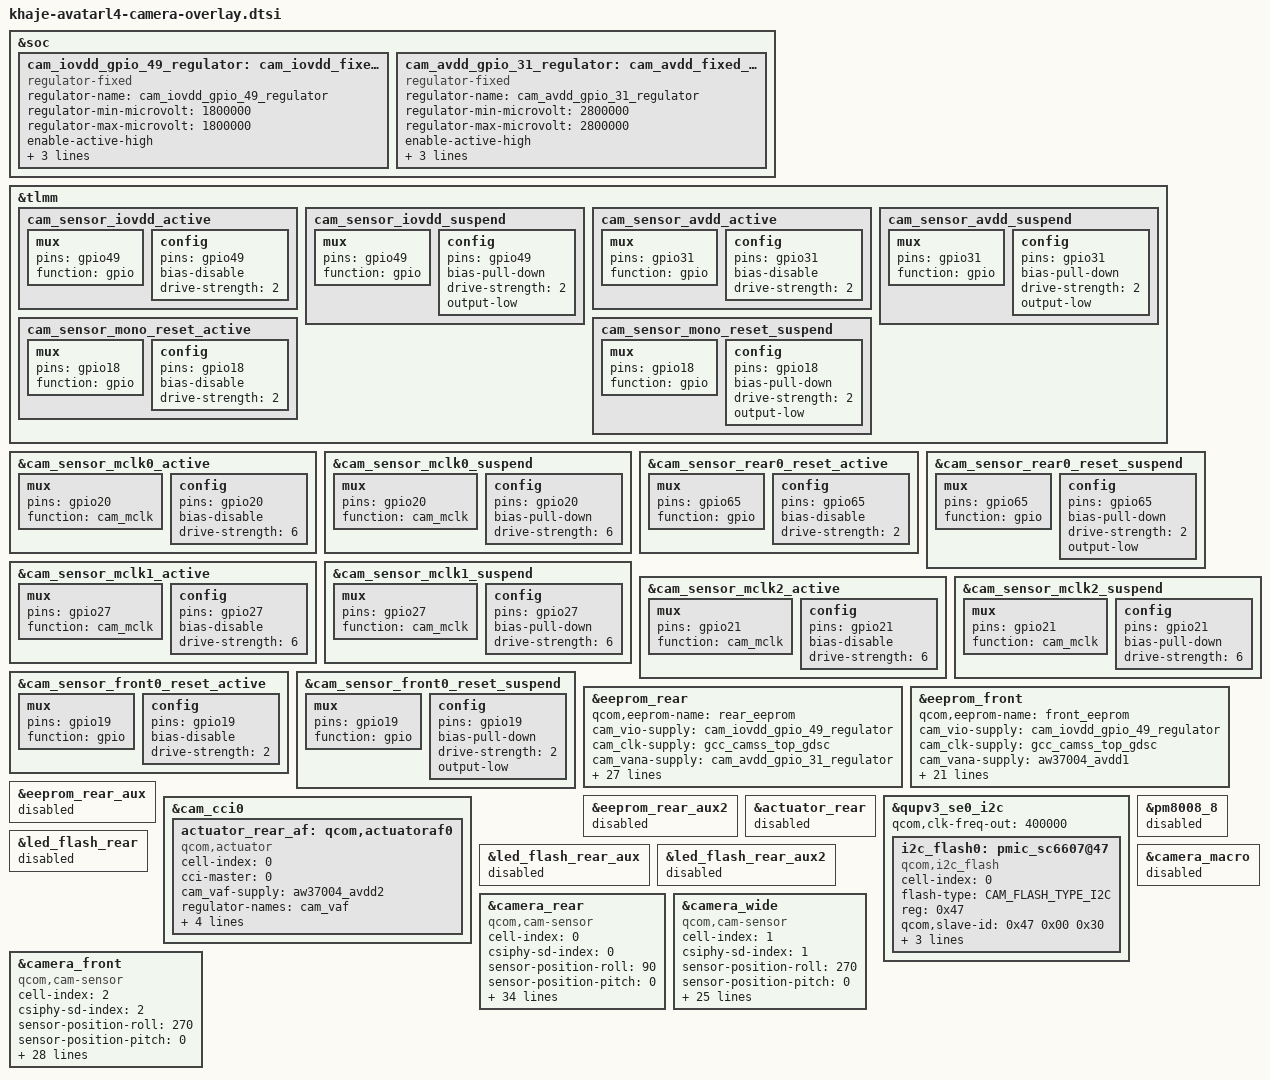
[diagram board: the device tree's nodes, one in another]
//khaje-camera-sensor-qrd.dtsi

&soc {
    cam_iovdd_gpio_49_regulator:cam_iovdd_fixed_regulator {
        compatible = "regulator-fixed";
        regulator-name = "cam_iovdd_gpio_49_regulator";
        regulator-min-microvolt = <1800000>;
        regulator-max-microvolt = <1800000>;
        enable-active-high;
        gpio = <&tlmm 49 0>;
        pinctrl-names = "cam_default","cam_suspend";
        pinctrl-0 = <&cam_sensor_iovdd_active>;
        pinctrl-1 = <&cam_sensor_iovdd_suspend>;
    };
    cam_avdd_gpio_31_regulator:cam_avdd_fixed_regulator {
        compatible = "regulator-fixed";
        regulator-name = "cam_avdd_gpio_31_regulator";
        regulator-min-microvolt = <2800000>;
        regulator-max-microvolt = <2800000>;
        enable-active-high;
        gpio = <&tlmm 31 0>;
        pinctrl-names = "cam_default","cam_suspend";
        pinctrl-0 = <&cam_sensor_avdd_active>;
        pinctrl-1 = <&cam_sensor_avdd_suspend>;
    };
};

&tlmm {

    cam_sensor_iovdd_active: cam_sensor_iovdd_active {
        mux {
            pins = "gpio49";
            function = "gpio";
        };
        config {
            pins = "gpio49";
            bias-disable; /* No PULL */
            drive-strength = <2>; /* 2 MA */
        };
    };
    cam_sensor_iovdd_suspend: cam_sensor_iovdd_suspend {
        mux {
            pins = "gpio49";
            function = "gpio";
        };
        config {
            pins = "gpio49";
            bias-pull-down; /* PULL DOWN */
            drive-strength = <2>; /* 2 MA */
            output-low;
        };
    };
    cam_sensor_avdd_active: cam_sensor_avdd_active {
        mux {
            pins = "gpio31";
            function = "gpio";
        };
        config {
            pins = "gpio31";
            bias-disable; /* No PULL */
            drive-strength = <2>; /* 2 MA */
        };
    };
    cam_sensor_avdd_suspend: cam_sensor_avdd_suspend {
        mux {
            pins = "gpio31";
            function = "gpio";
        };
        config {
            pins = "gpio31";
            bias-pull-down; /* PULL DOWN */
            drive-strength = <2>; /* 2 MA */
            output-low;
        };
    };

    cam_sensor_mono_reset_active: cam_sensor_mono_reset_active {
        mux {
            pins = "gpio18";
            function = "gpio";
        };
        config {
            pins = "gpio18";
            bias-disable; /* No PULL */
            drive-strength = <2>; /* 2 MA */
        };
    };
    cam_sensor_mono_reset_suspend: cam_sensor_mono_reset_suspend {
        mux {
            pins = "gpio18";
            function = "gpio";
        };
        config {
            pins = "gpio18";
            bias-pull-down; /* PULL DOWN */
            drive-strength = <2>; /* 2 MA */
            output-low;
        };
    };
};

&cam_sensor_mclk0_active {
    /* MCLK 0*/
    mux {
        pins = "gpio20";
        function = "cam_mclk";
    };

    config {
        pins = "gpio20";
        bias-disable; /* No PULL */
        drive-strength = <6>; /* 2 MA */
    };
};

&cam_sensor_mclk0_suspend {
    /* MCLK 0*/
    mux {
        pins = "gpio20";
        function = "cam_mclk";
    };

    config {
        pins = "gpio20";
        bias-pull-down; /* PULL DOWN */
        drive-strength = <6>; /* 2 MA */
    };
};

&cam_sensor_rear0_reset_active {
    mux {
        pins = "gpio65";
        function = "gpio";
    };
    config {
        pins = "gpio65";
        bias-disable; /* No PULL */
        drive-strength = <2>; /* 2 MA */
    };
};

&cam_sensor_rear0_reset_suspend {
    mux {
        pins = "gpio65";
        function = "gpio";
    };
    config {
        pins = "gpio65";
        bias-pull-down; /* PULL DOWN */
        drive-strength = <2>; /* 2 MA */
        output-low;
    };
};

&cam_sensor_mclk1_active {
    /* MCLK 1*/
    mux {
        pins = "gpio27";
        function = "cam_mclk";
    };

    config {
        pins = "gpio27";
        bias-disable; /* No PULL */
        drive-strength = <6>; /* 2 MA */
    };
};
&cam_sensor_mclk1_suspend {
    /* MCLK 1*/
    mux {
        pins = "gpio27";
        function = "cam_mclk";
    };

    config {
        pins = "gpio27";
        bias-pull-down; /* PULL DOWN */
        drive-strength = <6>; /* 2 MA */
    };
};

&cam_sensor_mclk2_active {
    /* MCLK 0*/
    mux {
        pins = "gpio21";
        function = "cam_mclk";
    };

    config {
        pins = "gpio21";
        bias-disable; /* No PULL */
        drive-strength = <6>; /* 2 MA */
    };
};

&cam_sensor_mclk2_suspend {
    /* MCLK 0*/
    mux {
        pins = "gpio21";
        function = "cam_mclk";
    };

    config {
        pins = "gpio21";
        bias-pull-down; /* PULL DOWN */
        drive-strength = <6>; /* 2 MA */
    };
};

&cam_sensor_front0_reset_active {
    mux {
        pins = "gpio19";
        function = "gpio";
    };
    config {
        pins = "gpio19";
        bias-disable; /* No PULL */
        drive-strength = <2>; /* 2 MA */
    };
};

&cam_sensor_front0_reset_suspend {
    mux {
        pins = "gpio19";
        function = "gpio";
    };
    config {
        pins = "gpio19";
        bias-pull-down; /* PULL DOWN */
        drive-strength = <2>; /* 2 MA */
        output-low;
    };
};

&eeprom_rear {
        qcom,eeprom-name = "rear_eeprom";
        cam_vio-supply = <&cam_iovdd_gpio_49_regulator>;
        cam_clk-supply = <&gcc_camss_top_gdsc>;
        cam_vana-supply = <&cam_avdd_gpio_31_regulator>;
        cam_vdig-supply = <&aw37004_dvdd1>;
        cam_v_custom1-supply = <&aw37004_avdd1>;
        regulator-names = "cam_vio","cam_clk","cam_vana","cam_vdig","cam_v_custom1";
        rgltr-cntrl-support;
        pwm-switch;
        rgltr-min-voltage = <1800000 0 2800000 1050000 2800000>;
        rgltr-max-voltage = <1800000 0 2800000 1050000 2800000>;
        rgltr-load-current = <120000 0 120000 120000 120000>;
        gpio-no-mux = <0>;
        pinctrl-names = "cam_default", "cam_suspend";
        pinctrl-0 = <&cam_sensor_mclk0_active
                     &cam_sensor_rear0_reset_active>;
        pinctrl-1 = <&cam_sensor_mclk0_suspend
                     &cam_sensor_rear0_reset_suspend>;
        gpios = <&tlmm 20 0>,
                <&tlmm 65 0>;
        gpio-reset = <1>;
        gpio-req-tbl-num = <0 1>;
        gpio-req-tbl-flags = <1 0>;
        gpio-req-tbl-label = "CAMIF_MCLK0",
                             "CAM_RESET0";
        sensor-mode = <0>;
        cci-master = <0>;
        status = "ok";
        clocks = <&gcc GCC_CAMSS_MCLK0_CLK>;
        clock-names = "cam_clk";
        clock-cntl-level = "turbo";
        clock-rates = <24000000>;
};

&eeprom_front {
        qcom,eeprom-name = "front_eeprom";
        cam_vio-supply = <&cam_iovdd_gpio_49_regulator>;
        cam_clk-supply = <&gcc_camss_top_gdsc>;
        cam_vana-supply = <&aw37004_avdd1>;
        cam_vdig-supply = <&aw37004_dvdd2>;
        regulator-names = "cam_vio","cam_clk","cam_vana","cam_vdig";
        rgltr-cntrl-support;
        pwm-switch;
        rgltr-min-voltage = <1800000 0 2800000 1200000>;
        rgltr-max-voltage = <1800000 0 2800000 1200000>;
        rgltr-load-current = <120000 0 120000 120000>;
        gpio-no-mux = <0>;
        pinctrl-names = "cam_default", "cam_suspend";
        pinctrl-0 = <&cam_sensor_mclk2_active
                     &cam_sensor_front0_reset_active>;
        pinctrl-1 = <&cam_sensor_mclk2_suspend
                     &cam_sensor_front0_reset_suspend>;
        gpios = <&tlmm 21 0>,
                <&tlmm 19 0>;
        gpio-reset = <1>;
        gpio-req-tbl-num = <0 1>;
        gpio-req-tbl-flags = <1 0>;
        gpio-req-tbl-label = "CAMIF_MCLK1",
                                "CAM_RESET1";
        cci-master = <1>;
        clocks = <&gcc GCC_CAMSS_MCLK1_CLK>;
        clock-rates = <24000000>;
};

&eeprom_rear_aux {
	status = "disabled";
};

&eeprom_rear_aux2 {
	status = "disabled";
};

&actuator_rear {
    status = "disable";
};

&qupv3_se0_i2c {
	status = "ok";
	qcom,clk-freq-out = <400000>;
	i2c_flash0:pmic_sc6607@47 {
			status = "ok";
			cell-index = <0>;
			compatible = "qcom,i2c_flash";
			flash-type = <CAM_FLASH_TYPE_I2C>;
			reg = <0x47>;
			qcom,slave-id = <0x47 0x00 0x30>;
			qcom,flash-name = "i2c_flash";
			qcom,flash-type = <1>;
			flash-index = <5>;
    };
};

&cam_cci0 {
        actuator_rear_af: qcom,actuatoraf0 {
                cell-index = <0>;
                compatible = "qcom,actuator";
                cci-master = <0>;
                cam_vaf-supply = <&aw37004_avdd2>;
                regulator-names = "cam_vaf";
                rgltr-cntrl-support;
                rgltr-min-voltage = <2800000>;
                rgltr-max-voltage = <2800000>;
                rgltr-load-current = <100000>;
                status = "ok";
        };
};

&pm8008_8 {
	status = "disabled";
};
&led_flash_rear {
	status = "disabled";
};

&led_flash_rear_aux{
    status = "disabled";
};
&led_flash_rear_aux2{
    status = "disabled";
};
&camera_rear {
        cell-index = <0>;
        compatible = "qcom,cam-sensor";
        csiphy-sd-index = <0>;
        sensor-position-roll = <90>;
        sensor-position-pitch = <0>;
        sensor-position-yaw = <180>;
        actuator-src = <&actuator_rear_af>;
        led-flash-src = <&i2c_flash0>;
        eeprom-src = <&eeprom_rear>;
        cam_vio-supply = <&cam_iovdd_gpio_49_regulator>;
        cam_clk-supply = <&gcc_camss_top_gdsc>;
        cam_vana-supply = <&cam_avdd_gpio_31_regulator>;
        cam_vdig-supply = <&aw37004_dvdd1>;
        cam_v_custom1-supply = <&aw37004_avdd1>;
        regulator-names = "cam_vio","cam_clk","cam_vana","cam_vdig","cam_v_custom1";
        rgltr-cntrl-support;
        pwm-switch;
        rgltr-min-voltage = <1800000 0 2800000 1050000 2800000>;
        rgltr-max-voltage = <1800000 0 2800000 1050000 2800000>;
        rgltr-load-current = <120000 0 120000 120000 120000>;
        gpio-no-mux = <0>;
        pinctrl-names = "cam_default", "cam_suspend";
        pinctrl-0 = <&cam_sensor_mclk0_active
                     &cam_sensor_rear0_reset_active>;
        pinctrl-1 = <&cam_sensor_mclk0_suspend
                     &cam_sensor_rear0_reset_suspend>;
        gpios = <&tlmm 20 0>,
                <&tlmm 65 0>;
        gpio-reset = <1>;
        gpio-req-tbl-num = <0 1>;
        gpio-req-tbl-flags = <1 0>;
        gpio-req-tbl-label = "CAMIF_MCLK0",
                             "CAM_RESET0";
        sensor-mode = <0>;
        cci-master = <0>;
        status = "ok";
        clocks = <&gcc GCC_CAMSS_MCLK0_CLK>;
        clock-names = "cam_clk";
        clock-cntl-level = "turbo";
        clock-rates = <24000000>;
};
// Mono
&camera_wide {
        cell-index = <1>;
        compatible = "qcom,cam-sensor";
        csiphy-sd-index = <1>;
        sensor-position-roll = <270>;
        sensor-position-pitch = <0>;
        sensor-position-yaw = <180>;
        cam_vio-supply = <&cam_iovdd_gpio_49_regulator>;
        cam_clk-supply = <&gcc_camss_top_gdsc>;
        cam_vana-supply = <&aw37004_avdd1>;
        regulator-names = "cam_vio","cam_clk","cam_vana";
        rgltr-cntrl-support;
        pwm-switch;
        rgltr-min-voltage = <1800000 0 2800000>;
        rgltr-max-voltage = <1800000 0 2800000>;
        rgltr-load-current = <120000 0 120000>;
        gpio-no-mux = <0>;
        pinctrl-names = "cam_default", "cam_suspend";
        pinctrl-0 = <&cam_sensor_mclk1_active
                     &cam_sensor_mono_reset_active>;
        pinctrl-1 = <&cam_sensor_mclk1_suspend
                     &cam_sensor_mono_reset_suspend>;
        gpios = <&tlmm 27 0>,
                <&tlmm 18 0>;
        gpio-reset = <1>;
        gpio-req-tbl-num = <0 1>;
        gpio-req-tbl-flags = <1 0>;
        gpio-req-tbl-label = "CAMIF_MCLK2",
                                "CAM_RESET2";
	    sensor-mode = <0>;
        cci-master = <1>;
	    status = "ok";
        clocks = <&gcc GCC_CAMSS_MCLK2_CLK>;
        clock-names = "cam_clk";
	    clock-cntl-level = "turbo";
        clock-rates = <24000000>;
};

&camera_macro {
	status = "disabled";
};

&camera_front {
	    cell-index = <2>;
	    compatible = "qcom,cam-sensor";
	    csiphy-sd-index = <2>;
	    sensor-position-roll = <270>;
	    sensor-position-pitch = <0>;
	    sensor-position-yaw = <0>;
        eeprom-src = <&eeprom_front>;
        cam_vio-supply = <&cam_iovdd_gpio_49_regulator>;
        cam_clk-supply = <&gcc_camss_top_gdsc>;
        cam_vana-supply = <&aw37004_avdd1>;
        cam_vdig-supply = <&aw37004_dvdd2>;
        regulator-names = "cam_vio","cam_clk","cam_vana","cam_vdig";
        rgltr-cntrl-support;
        pwm-switch;
        rgltr-min-voltage = <1800000 0 2800000 1200000>;
        rgltr-max-voltage = <1800000 0 2800000 1200000>;
        rgltr-load-current = <120000 0 120000 120000>;
        gpio-no-mux = <0>;
        pinctrl-names = "cam_default", "cam_suspend";
        pinctrl-0 = <&cam_sensor_mclk2_active
                     &cam_sensor_front0_reset_active>;
        pinctrl-1 = <&cam_sensor_mclk2_suspend
                     &cam_sensor_front0_reset_suspend>;
        gpios = <&tlmm 21 0>,
                <&tlmm 19 0>;
        gpio-reset = <1>;
        gpio-req-tbl-num = <0 1>;
        gpio-req-tbl-flags = <1 0>;
        gpio-req-tbl-label = "CAMIF_MCLK1",
                                "CAM_RESET1";
	    sensor-mode = <0>;
        cci-master = <1>;
	    status = "ok";
        clocks = <&gcc GCC_CAMSS_MCLK1_CLK>;
	    clock-names = "cam_clk";
	    clock-cntl-level = "turbo";
        clock-rates = <24000000>;
};
